AUTOSAR XML (schema 2.1.2)
package /ComponentType
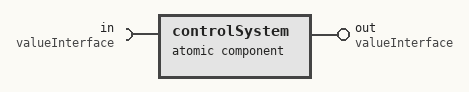
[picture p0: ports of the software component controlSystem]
  atomic software component type controlSystem
    provide port out: provided-interface=valueInterface
    require port in: required-interface=valueInterface
